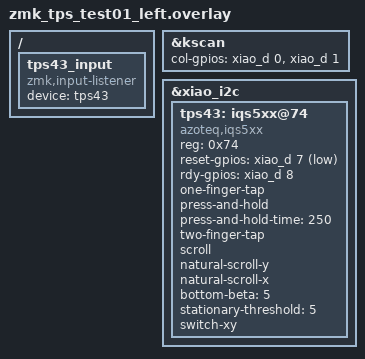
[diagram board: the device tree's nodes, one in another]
// This file was generated from a template. Edit it to match your keyboard.
// See https://zmk.dev/docs/development/hardware-integration/new-shield for more
// instructions.

#include "zmk_tps_test01.dtsi"

&kscan {
    // Replace these comments with the GPIO pins in the matrix for the left side.
    // See https://zmk.dev/docs/development/hardware-integration/new-shield#shield-overlays
    col-gpios
        = <&xiao_d 0 GPIO_ACTIVE_HIGH>
        , <&xiao_d 1 GPIO_ACTIVE_HIGH>
        ;
};


/ {
    tps43_input: tps43_input {
        compatible = "zmk,input-listener";
        device = <&tps43>;
    };
};

&xiao_i2c {
    status = "okay";
    tps43: iqs5xx@74 {
        status = "okay";
        compatible = "azoteq,iqs5xx";
        reg = <0x74>;

        reset-gpios = <&xiao_d 7 GPIO_ACTIVE_LOW>;
        rdy-gpios = <&xiao_d 8 GPIO_ACTIVE_HIGH>;

        /*
         * Potentially non-exhaustive list of configuration options.
         * See: dts/bindings/input/azoteq,iqs5xx-common.yaml for a full list.
         */
        one-finger-tap;
        press-and-hold;
        press-and-hold-time = <250>;
        two-finger-tap;

        scroll;
        natural-scroll-y;
        natural-scroll-x;

        bottom-beta = <5>;
        stationary-threshold = <5>;

        switch-xy;
    };
};
